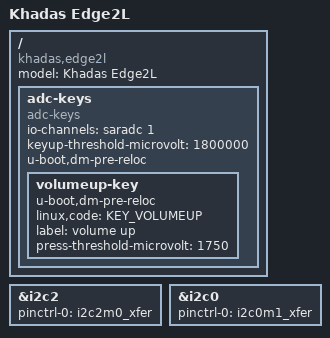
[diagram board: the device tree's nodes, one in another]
// SPDX-License-Identifier: (GPL-2.0+ OR MIT)
/*
 * Copyright (c) 2023 Rockchip Electronics Co., Ltd.
 */

/dts-v1/;
#include "rk3576.dtsi"
#include "rk3576-u-boot.dtsi"
#include <dt-bindings/input/input.h>

/ {
	model = "Khadas Edge2L";
	compatible = "khadas,edge2l", "rockchip,rk3576";

	adc-keys {
		compatible = "adc-keys";
		io-channels = <&saradc 1>;
		io-channel-names = "buttons";
		keyup-threshold-microvolt = <1800000>;
		u-boot,dm-pre-reloc;
		status = "okay";

		volumeup-key {
			u-boot,dm-pre-reloc;
			linux,code = <KEY_VOLUMEUP>;
			label = "volume up";
			press-threshold-microvolt = <1750>;
		};
	};
};

&i2c2 {
	status = "okay";
	pinctrl-names = "default";
	pinctrl-0 = <&i2c2m0_xfer>;
};

&i2c0 {
	status = "okay";
	pinctrl-names = "default";
	pinctrl-0 = <&i2c0m1_xfer>;
};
